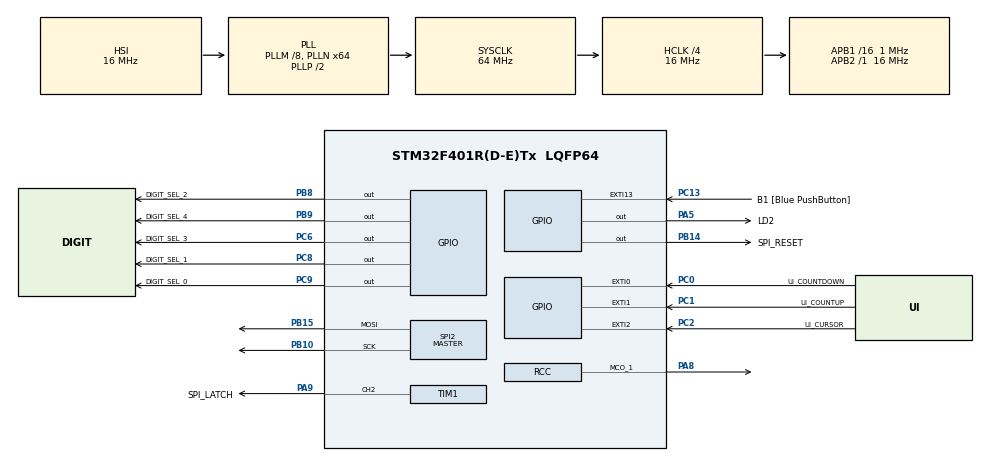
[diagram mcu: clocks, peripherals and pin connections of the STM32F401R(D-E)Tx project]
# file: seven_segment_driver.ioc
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Mcu.Family=STM32F4
Mcu.Name=STM32F401R(D-E)Tx
Mcu.Package=LQFP64
NVIC.EXTI15_10_IRQn=true\:0\:0\:false\:false\:true\:true\:true\:true
NVIC.PriorityGroup=NVIC_PRIORITYGROUP_4
NVIC.SPI2_IRQn=true\:0\:0\:false\:false\:true\:true\:true\:true
NVIC.TIM1_UP_TIM10_IRQn=true\:0\:0\:false\:false\:true\:true\:true\:true
NVIC.TIM2_IRQn=true\:0\:0\:false\:false\:true\:true\:true\:true
PA13.GPIO_Label=TMS
PA13.Mode=Trace_Asynchronous_SW
PA13.Signal=SYS_JTMS-SWDIO
PA14.GPIO_Label=TCK
PA14.Mode=Trace_Asynchronous_SW
PA14.Signal=SYS_JTCK-SWCLK
PA5.GPIO_Label=LD2
PA5.GPIO_Mode=GPIO_MODE_OUTPUT_PP
PA5.GPIO_PuPd=GPIO_NOPULL
PA5.GPIO_Speed=GPIO_SPEED_FREQ_LOW
PA5.Signal=GPIO_Output
PA8.Mode=Clock-out-1
PA8.Signal=RCC_MCO_1
PA9.GPIO_Label=SPI_LATCH
PA9.Signal=S_TIM1_CH2
PB10.Mode=TX_Only_Simplex_Unidirect_Master
PB10.Signal=SPI2_SCK
PB14.GPIO_Label=SPI_RESET
PB14.GPIO_PuPd=GPIO_PULLUP
PB14.Signal=GPIO_Output
PB15.GPIO_PuPd=GPIO_NOPULL
PB15.Mode=TX_Only_Simplex_Unidirect_Master
PB15.Signal=SPI2_MOSI
PB3.GPIO_Label=SWO
PB3.Mode=Trace_Asynchronous_SW
PB3.Signal=SYS_JTDO-SWO
PB8.GPIO_Label=DIGIT_SEL_2
PB8.Signal=GPIO_Output
PB9.GPIO_Label=DIGIT_SEL_4
PB9.Signal=GPIO_Output
PC0.GPIO_Label=UI_COUNTDOWN
PC0.GPIO_PuPd=GPIO_PULLUP
PC0.Signal=GPXTI0
PC1.GPIO_Label=UI_COUNTUP
PC1.GPIO_PuPd=GPIO_PULLUP
PC1.Signal=GPXTI1
PC13-ANTI_TAMP.GPIO_Label=B1 [Blue PushButton]
PC13-ANTI_TAMP.GPIO_ModeDefaultEXTI=GPIO_MODE_IT_FALLING
PC13-ANTI_TAMP.GPIO_PuPd=GPIO_NOPULL
PC13-ANTI_TAMP.Signal=GPXTI13
PC14-OSC32_IN.Mode=LSE-External-Oscillator
PC14-OSC32_IN.Signal=RCC_OSC32_IN
PC15-OSC32_OUT.Mode=LSE-External-Oscillator
PC15-OSC32_OUT.Signal=RCC_OSC32_OUT
PC2.GPIO_Label=UI_CURSOR
PC2.GPIO_PuPd=GPIO_PULLUP
PC2.Signal=GPXTI2
PC6.GPIO_Label=DIGIT_SEL_3
PC6.Signal=GPIO_Output
PC8.GPIO_Label=DIGIT_SEL_1
PC8.Signal=GPIO_Output
PC9.GPIO_Label=DIGIT_SEL_0
PC9.Signal=GPIO_Output
PH0\ -\ OSC_IN.Mode=HSE-External-Clock-Source
PH0\ -\ OSC_IN.Signal=RCC_OSC_IN
PH1\ -\ OSC_OUT.Mode=HSE-External-Clock-Source
PH1\ -\ OSC_OUT.Signal=RCC_OSC_OUT
ProjectManager.HeapSize=0x200
ProjectManager.StackSize=0x400
ProjectManager.TargetToolchain=CMake
RCC.48MHZClocksFreq_Value=18285714.285714287
RCC.AHBCLKDivider=RCC_SYSCLK_DIV4
RCC.AHBFreq_Value=16000000
RCC.APB1CLKDivider=RCC_HCLK_DIV16
RCC.APB1Freq_Value=1000000
RCC.APB1TimFreq_Value=2000000
RCC.APB2Freq_Value=16000000
RCC.APB2TimFreq_Value=16000000
RCC.CortexFreq_Value=16000000
RCC.HCLKFreq_Value=16000000
RCC.HSE_VALUE=8000000
RCC.HSI_VALUE=16000000
RCC.PLLM=8
RCC.PLLN=64
RCC.PLLQ=7
RCC.SYSCLKFreq_VALUE=64000000
RCC.SYSCLKSource=RCC_SYSCLKSOURCE_PLLCLK
RCC.VCOOutputFreq_Value=128000000
SH.S_TIM1_CH2.0=TIM1_CH2,Output Compare2 CH2
SPI2.BaudRatePrescaler=SPI_BAUDRATEPRESCALER_2
SPI2.Direction=SPI_DIRECTION_2LINES
SPI2.Mode=SPI_MODE_MASTER
SPI2.VirtualType=VM_MASTER
TIM1.Channel-Output\ Compare2\ CH2=TIM_CHANNEL_2
TIM1.Period=1
TIM1.Prescaler=16-1
TIM1.Pulse-Output\ Compare2\ CH2=16-1
TIM2.Period=2000-1
TIM2.Prescaler=2-1
VP_TIM1_VS_ClockSourceINT.Mode=Internal
VP_TIM1_VS_OPM.Mode=OPM_bit
VP_TIM2_VS_ClockSourceINT.Mode=Internal
board=NUCLEO-F401RE

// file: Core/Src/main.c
/* USER CODE BEGIN Header */
/**
  ******************************************************************************
  * @file           : main.c
  * @brief          : Main program body
  ******************************************************************************
  * @attention
  *
  * Copyright (c) 2025 STMicroelectronics.
  * All rights reserved.
  *
  * This software is licensed under terms that can be found in the LICENSE file
  * in the root directory of this software component.
  * If no LICENSE file comes with this software, it is provided AS-IS.
  *
  ******************************************************************************
  */
/* USER CODE END Header */
#include "main.h"

SPI_HandleTypeDef hspi2;

TIM_HandleTypeDef htim1;
TIM_HandleTypeDef htim2;

/* USER CODE BEGIN PV */

SEVSEG_DISPLAY_TypeDef sevseg;

/* USER CODE END PV */

void SystemClock_Config(void);
static void MX_GPIO_Init(void);
static void MX_SPI2_Init(void);
static void MX_TIM1_Init(void);
static void MX_TIM2_Init(void);

int main(void)
{

  /* MCU Configuration--------------------------------------------------------*/

  /* Reset of all peripherals, Initializes the Flash interface and the Systick. */
  HAL_Init();

  /* Configure the system clock */
  SystemClock_Config();

  /* Initialize all configured peripherals */
  MX_GPIO_Init();
  MX_SPI2_Init();
  MX_TIM1_Init();
  MX_TIM2_Init();
  /* USER CODE BEGIN 2 */

  app_main();

  /* USER CODE END 2 */

  /* Infinite loop */
  while (1)
  {

  }
}

void SystemClock_Config(void)
{
  RCC_OscInitTypeDef RCC_OscInitStruct = {0};
  RCC_ClkInitTypeDef RCC_ClkInitStruct = {0};

  /** Configure the main internal regulator output voltage
  */
  __HAL_RCC_PWR_CLK_ENABLE();
  __HAL_PWR_VOLTAGESCALING_CONFIG(PWR_REGULATOR_VOLTAGE_SCALE2);

  /** Initializes the RCC Oscillators according to the specified parameters
  * in the RCC_OscInitTypeDef structure.
  */
  RCC_OscInitStruct.OscillatorType = RCC_OSCILLATORTYPE_HSI;
  RCC_OscInitStruct.HSIState = RCC_HSI_ON;
  RCC_OscInitStruct.HSICalibrationValue = RCC_HSICALIBRATION_DEFAULT;
  RCC_OscInitStruct.PLL.PLLState = RCC_PLL_ON;
  RCC_OscInitStruct.PLL.PLLSource = RCC_PLLSOURCE_HSI;
  RCC_OscInitStruct.PLL.PLLM = 8;
  RCC_OscInitStruct.PLL.PLLN = 64;
  RCC_OscInitStruct.PLL.PLLP = RCC_PLLP_DIV2;
  RCC_OscInitStruct.PLL.PLLQ = 7;
  if (HAL_RCC_OscConfig(&RCC_OscInitStruct) != HAL_OK)
  {
    Error_Handler();
  }

  /** Initializes the CPU, AHB and APB buses clocks
  */
  RCC_ClkInitStruct.ClockType = RCC_CLOCKTYPE_HCLK|RCC_CLOCKTYPE_SYSCLK
                              |RCC_CLOCKTYPE_PCLK1|RCC_CLOCKTYPE_PCLK2;
  RCC_ClkInitStruct.SYSCLKSource = RCC_SYSCLKSOURCE_PLLCLK;
  RCC_ClkInitStruct.AHBCLKDivider = RCC_SYSCLK_DIV4;
  RCC_ClkInitStruct.APB1CLKDivider = RCC_HCLK_DIV16;
  RCC_ClkInitStruct.APB2CLKDivider = RCC_HCLK_DIV1;

  if (HAL_RCC_ClockConfig(&RCC_ClkInitStruct, FLASH_LATENCY_0) != HAL_OK)
  {
    Error_Handler();
  }
  HAL_RCC_MCOConfig(RCC_MCO1, RCC_MCO1SOURCE_HSI, RCC_MCODIV_1);
}

static void MX_SPI2_Init(void)
{

  /* SPI2 parameter configuration*/
  hspi2.Instance = SPI2;
  hspi2.Init.Mode = SPI_MODE_MASTER;
  hspi2.Init.Direction = SPI_DIRECTION_2LINES;
  hspi2.Init.DataSize = SPI_DATASIZE_8BIT;
  hspi2.Init.CLKPolarity = SPI_POLARITY_LOW;
  hspi2.Init.CLKPhase = SPI_PHASE_1EDGE;
  hspi2.Init.NSS = SPI_NSS_SOFT;
  hspi2.Init.BaudRatePrescaler = SPI_BAUDRATEPRESCALER_2;
  hspi2.Init.FirstBit = SPI_FIRSTBIT_MSB;
  hspi2.Init.TIMode = SPI_TIMODE_DISABLE;
  hspi2.Init.CRCCalculation = SPI_CRCCALCULATION_DISABLE;
  hspi2.Init.CRCPolynomial = 10;
  if (HAL_SPI_Init(&hspi2) != HAL_OK)
  {
    Error_Handler();
  }

}

static void MX_TIM1_Init(void)
{

  TIM_ClockConfigTypeDef sClockSourceConfig = {0};
  TIM_MasterConfigTypeDef sMasterConfig = {0};
  TIM_OC_InitTypeDef sConfigOC = {0};
  TIM_BreakDeadTimeConfigTypeDef sBreakDeadTimeConfig = {0};

  htim1.Instance = TIM1;
  htim1.Init.Prescaler = 16-1;
  htim1.Init.CounterMode = TIM_COUNTERMODE_UP;
  htim1.Init.Period = 1;
  htim1.Init.ClockDivision = TIM_CLOCKDIVISION_DIV1;
  htim1.Init.RepetitionCounter = 0;
  htim1.Init.AutoReloadPreload = TIM_AUTORELOAD_PRELOAD_DISABLE;
  if (HAL_TIM_Base_Init(&htim1) != HAL_OK)
  {
    Error_Handler();
  }
  sClockSourceConfig.ClockSource = TIM_CLOCKSOURCE_INTERNAL;
  if (HAL_TIM_ConfigClockSource(&htim1, &sClockSourceConfig) != HAL_OK)
  {
    Error_Handler();
  }
  if (HAL_TIM_OC_Init(&htim1) != HAL_OK)
  {
    Error_Handler();
  }
  if (HAL_TIM_OnePulse_Init(&htim1, TIM_OPMODE_SINGLE) != HAL_OK)
  {
    Error_Handler();
  }
  sMasterConfig.MasterOutputTrigger = TIM_TRGO_RESET;
  sMasterConfig.MasterSlaveMode = TIM_MASTERSLAVEMODE_DISABLE;
  if (HAL_TIMEx_MasterConfigSynchronization(&htim1, &sMasterConfig) != HAL_OK)
  {
    Error_Handler();
  }
  sConfigOC.OCMode = TIM_OCMODE_TIMING;
  sConfigOC.Pulse = 16-1;
  sConfigOC.OCPolarity = TIM_OCPOLARITY_HIGH;
  sConfigOC.OCNPolarity = TIM_OCNPOLARITY_HIGH;
  sConfigOC.OCFastMode = TIM_OCFAST_DISABLE;
  sConfigOC.OCIdleState = TIM_OCIDLESTATE_RESET;
  sConfigOC.OCNIdleState = TIM_OCNIDLESTATE_RESET;
  if (HAL_TIM_OC_ConfigChannel(&htim1, &sConfigOC, TIM_CHANNEL_2) != HAL_OK)
  {
    Error_Handler();
  }
  sBreakDeadTimeConfig.OffStateRunMode = TIM_OSSR_DISABLE;
  sBreakDeadTimeConfig.OffStateIDLEMode = TIM_OSSI_DISABLE;
  sBreakDeadTimeConfig.LockLevel = TIM_LOCKLEVEL_OFF;
  sBreakDeadTimeConfig.DeadTime = 0;
  sBreakDeadTimeConfig.BreakState = TIM_BREAK_DISABLE;
  sBreakDeadTimeConfig.BreakPolarity = TIM_BREAKPOLARITY_HIGH;
  sBreakDeadTimeConfig.AutomaticOutput = TIM_AUTOMATICOUTPUT_DISABLE;
  if (HAL_TIMEx_ConfigBreakDeadTime(&htim1, &sBreakDeadTimeConfig) != HAL_OK)
  {
    Error_Handler();
  }
  HAL_TIM_MspPostInit(&htim1);

}

static void MX_TIM2_Init(void)
{

  TIM_ClockConfigTypeDef sClockSourceConfig = {0};
  TIM_MasterConfigTypeDef sMasterConfig = {0};

  htim2.Instance = TIM2;
  htim2.Init.Prescaler = 2-1;
  htim2.Init.CounterMode = TIM_COUNTERMODE_UP;
  htim2.Init.Period = 2000-1;
  htim2.Init.ClockDivision = TIM_CLOCKDIVISION_DIV1;
  htim2.Init.AutoReloadPreload = TIM_AUTORELOAD_PRELOAD_DISABLE;
  if (HAL_TIM_Base_Init(&htim2) != HAL_OK)
  {
    Error_Handler();
  }
  sClockSourceConfig.ClockSource = TIM_CLOCKSOURCE_INTERNAL;
  if (HAL_TIM_ConfigClockSource(&htim2, &sClockSourceConfig) != HAL_OK)
  {
    Error_Handler();
  }
  sMasterConfig.MasterOutputTrigger = TIM_TRGO_RESET;
  sMasterConfig.MasterSlaveMode = TIM_MASTERSLAVEMODE_DISABLE;
  if (HAL_TIMEx_MasterConfigSynchronization(&htim2, &sMasterConfig) != HAL_OK)
  {
    Error_Handler();
  }

}

static void MX_GPIO_Init(void)
{
  GPIO_InitTypeDef GPIO_InitStruct = {0};

  /* GPIO Ports Clock Enable */
  __HAL_RCC_GPIOC_CLK_ENABLE();
  __HAL_RCC_GPIOH_CLK_ENABLE();
  __HAL_RCC_GPIOA_CLK_ENABLE();
  __HAL_RCC_GPIOB_CLK_ENABLE();

  /*Configure GPIO pin Output Level */
  HAL_GPIO_WritePin(LD2_GPIO_Port, LD2_Pin, GPIO_PIN_RESET);

  /*Configure GPIO pin Output Level */
  HAL_GPIO_WritePin(GPIOB, SPI_RESET_Pin|DIGIT_SEL_2_Pin|DIGIT_SEL_4_Pin, GPIO_PIN_RESET);

  /*Configure GPIO pin Output Level */
  HAL_GPIO_WritePin(GPIOC, DIGIT_SEL_3_Pin|DIGIT_SEL_1_Pin|DIGIT_SEL_0_Pin, GPIO_PIN_RESET);

  /*Configure GPIO pin : B1_Pin */
  GPIO_InitStruct.Pin = B1_Pin;
  GPIO_InitStruct.Mode = GPIO_MODE_IT_FALLING;
  GPIO_InitStruct.Pull = GPIO_NOPULL;
  HAL_GPIO_Init(B1_GPIO_Port, &GPIO_InitStruct);

  /*Configure GPIO pins : UI_COUNTDOWN_Pin UI_COUNTUP_Pin UI_CURSOR_Pin */
  GPIO_InitStruct.Pin = UI_COUNTDOWN_Pin|UI_COUNTUP_Pin|UI_CURSOR_Pin;
  GPIO_InitStruct.Mode = GPIO_MODE_IT_RISING;
  GPIO_InitStruct.Pull = GPIO_PULLUP;
  HAL_GPIO_Init(GPIOC, &GPIO_InitStruct);

  /*Configure GPIO pin : LD2_Pin */
  GPIO_InitStruct.Pin = LD2_Pin;
  GPIO_InitStruct.Mode = GPIO_MODE_OUTPUT_PP;
  GPIO_InitStruct.Pull = GPIO_NOPULL;
  GPIO_InitStruct.Speed = GPIO_SPEED_FREQ_LOW;
  HAL_GPIO_Init(LD2_GPIO_Port, &GPIO_InitStruct);

  /*Configure GPIO pin : SPI_RESET_Pin */
  GPIO_InitStruct.Pin = SPI_RESET_Pin;
  GPIO_InitStruct.Mode = GPIO_MODE_OUTPUT_PP;
  GPIO_InitStruct.Pull = GPIO_PULLUP;
  GPIO_InitStruct.Speed = GPIO_SPEED_FREQ_LOW;
  HAL_GPIO_Init(SPI_RESET_GPIO_Port, &GPIO_InitStruct);

  /*Configure GPIO pins : DIGIT_SEL_3_Pin DIGIT_SEL_1_Pin DIGIT_SEL_0_Pin */
  GPIO_InitStruct.Pin = DIGIT_SEL_3_Pin|DIGIT_SEL_1_Pin|DIGIT_SEL_0_Pin;
  GPIO_InitStruct.Mode = GPIO_MODE_OUTPUT_PP;
  GPIO_InitStruct.Pull = GPIO_NOPULL;
  GPIO_InitStruct.Speed = GPIO_SPEED_FREQ_LOW;
  HAL_GPIO_Init(GPIOC, &GPIO_InitStruct);

  /*Configure GPIO pin : PA8 */
  GPIO_InitStruct.Pin = GPIO_PIN_8;
  GPIO_InitStruct.Mode = GPIO_MODE_AF_PP;
  GPIO_InitStruct.Pull = GPIO_NOPULL;
  GPIO_InitStruct.Speed = GPIO_SPEED_FREQ_LOW;
  GPIO_InitStruct.Alternate = GPIO_AF0_MCO;
  HAL_GPIO_Init(GPIOA, &GPIO_InitStruct);

  /*Configure GPIO pins : DIGIT_SEL_2_Pin DIGIT_SEL_4_Pin */
  GPIO_InitStruct.Pin = DIGIT_SEL_2_Pin|DIGIT_SEL_4_Pin;
  GPIO_InitStruct.Mode = GPIO_MODE_OUTPUT_PP;
  GPIO_InitStruct.Pull = GPIO_NOPULL;
  GPIO_InitStruct.Speed = GPIO_SPEED_FREQ_LOW;
  HAL_GPIO_Init(GPIOB, &GPIO_InitStruct);

  /* EXTI interrupt init*/
  HAL_NVIC_SetPriority(EXTI15_10_IRQn, 0, 0);
  HAL_NVIC_EnableIRQ(EXTI15_10_IRQn);

}

void Error_Handler(void)
{
  __disable_irq();
  while (1)
  {
  }
}
